# STM32F40x register map
File version: 1.5
Registers are 32-bit, read-write, reset 0x0 unless marked. A register's access mark holds for its fields unless they carry their own. Offsets are from the block's base; [hi:lo] are bit positions; {n}, {i} and the like mark numbered series; 'fields as' and 'values as' point back to an identical list.

## FSMC（静态存储器控制） — FSMC：NOR/PSRAM/NAND 外部存储器控制 | Flexible static memory controller
Base 0xA0000000
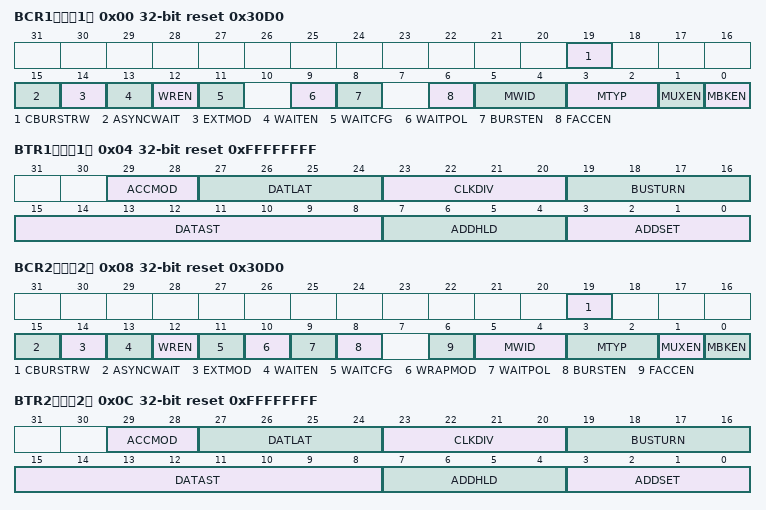
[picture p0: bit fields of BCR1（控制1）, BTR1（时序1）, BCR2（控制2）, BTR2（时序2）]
0x00 BCR1（控制1） reset 0x30D0 — 存储块1 控制（SRAM/PSRAM/NOR） | SRAM/NOR-Flash chip-select control register 1
  [19] CBURSTRW, [15] ASYNCWAIT, [14] EXTMOD, [13] WAITEN, [12] WREN, [11] WAITCFG, [9] WAITPOL, [8] BURSTEN, [6] FACCEN, [5:4] MWID, [3:2] MTYP, [1] MUXEN, [0] MBKEN
0x04 BTR1（时序1） reset 0xFFFFFFFF — 存储块1 读写时序 | SRAM/NOR-Flash chip-select timing register 1
  [29:28] ACCMOD, [27:24] DATLAT, [23:20] CLKDIV, [19:16] BUSTURN, [15:8] DATAST, [7:4] ADDHLD, [3:0] ADDSET
0x08 BCR2（控制2） reset 0x30D0 — 存储块2 控制 | SRAM/NOR-Flash chip-select control register 2
  [19] CBURSTRW, [15] ASYNCWAIT, [14] EXTMOD, [13] WAITEN, [12] WREN, [11] WAITCFG, [10] WRAPMOD, [9] WAITPOL, [8] BURSTEN, [6] FACCEN, [5:4] MWID, [3:2] MTYP, [1] MUXEN, [0] MBKEN
0x0C BTR2（时序2） reset 0xFFFFFFFF — 存储块2 读写时序 | SRAM/NOR-Flash chip-select timing register 2
  fields as BTR1（时序1）
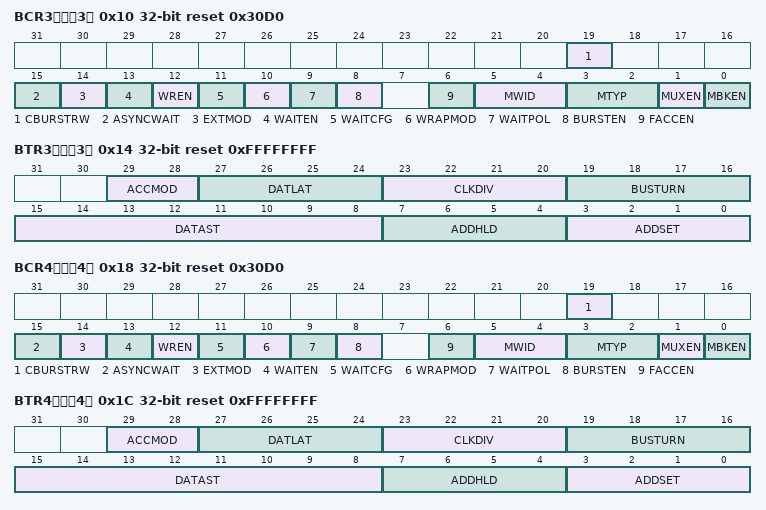
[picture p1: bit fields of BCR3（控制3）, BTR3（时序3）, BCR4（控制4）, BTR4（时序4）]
0x10 BCR3（控制3） reset 0x30D0 — 存储块3 控制 | SRAM/NOR-Flash chip-select control register 3
  fields as BCR2（控制2）
0x14 BTR3（时序3） reset 0xFFFFFFFF — 存储块3 读写时序 | SRAM/NOR-Flash chip-select timing register 3
  fields as BTR1（时序1）
0x18 BCR4（控制4） reset 0x30D0 — 存储块4 控制 | SRAM/NOR-Flash chip-select control register 4
  fields as BCR2（控制2）
0x1C BTR4（时序4） reset 0xFFFFFFFF — 存储块4 读写时序 | SRAM/NOR-Flash chip-select timing register 4
  fields as BTR1（时序1）
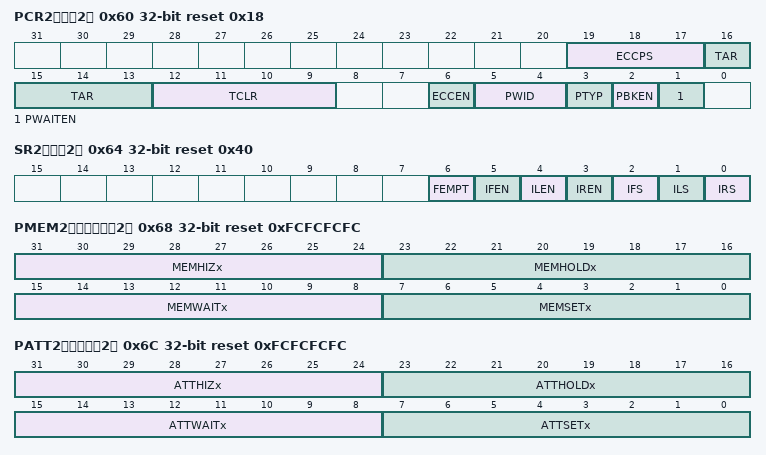
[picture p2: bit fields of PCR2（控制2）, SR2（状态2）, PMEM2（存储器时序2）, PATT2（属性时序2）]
0x60 PCR2（控制2） reset 0x18 — 存储块2 控制（NAND） | PC Card/NAND Flash control register 2
  [19:17] ECCPS, [16:13] TAR, [12:9] TCLR, [6] ECCEN, [5:4] PWID, [3] PTYP, [2] PBKEN, [1] PWAITEN
0x64 SR2（状态2） access per field reset 0x40 — 存储块2 状态（NAND） | FIFO status and interrupt register 2
  [6] FEMPT ro, [5] IFEN rw, [4] ILEN rw, [3] IREN rw, [2] IFS rw, [1] ILS rw, [0] IRS rw
0x68 PMEM2（存储器时序2） reset 0xFCFCFCFC — 存储块2 通用存储器时序（NAND） | Common memory space timing register 2
  [31:24] MEMHIZx, [23:16] MEMHOLDx, [15:8] MEMWAITx, [7:0] MEMSETx
0x6C PATT2（属性时序2） reset 0xFCFCFCFC — 存储块2 属性存储器时序（NAND） | Attribute memory space timing register 2
  [31:24] ATTHIZx, [23:16] ATTHOLDx, [15:8] ATTWAITx, [7:0] ATTSETx
0x74 ECCR2（块2 ECC） ro — 存储块2 ECC 结果（NAND） | ECC result register 2
  [31:0] ECCx
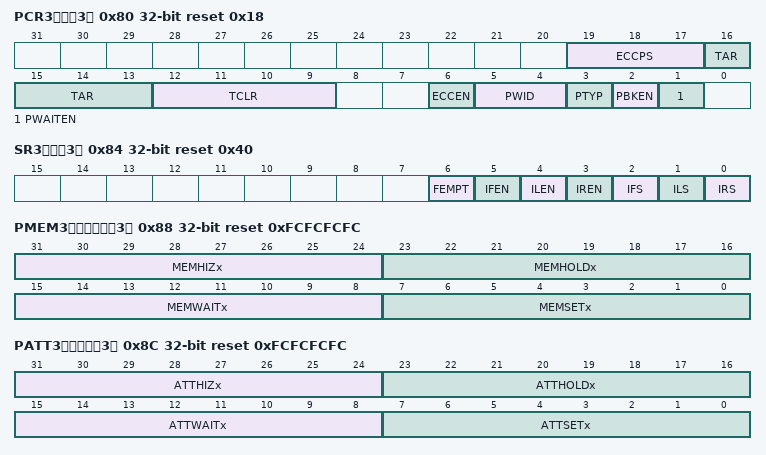
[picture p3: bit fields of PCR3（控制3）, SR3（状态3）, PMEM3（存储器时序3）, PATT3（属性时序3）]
0x80 PCR3（控制3） reset 0x18 — 存储块3 控制（NAND） | PC Card/NAND Flash control register 3
  fields as PCR2（控制2）
0x84 SR3（状态3） access per field reset 0x40 — 存储块3 状态（NAND） | FIFO status and interrupt register 3
  fields as SR2（状态2）
0x88 PMEM3（存储器时序3） reset 0xFCFCFCFC — 存储块3 通用存储器时序（NAND） | Common memory space timing register 3
  [31:24] MEMHIZx, [23:16] MEMHOLDx, [15:8] MEMWAITx, [7:0] MEMSETx
0x8C PATT3（属性时序3） reset 0xFCFCFCFC — 存储块3 属性存储器时序（NAND） | Attribute memory space timing register 3
  [31:24] ATTHIZx, [23:16] ATTHOLDx, [15:8] ATTWAITx, [7:0] ATTSETx
0x94 ECCR3（块3 ECC） ro — 存储块3 ECC 结果（NAND） | ECC result register 3
  [31:0] ECCx
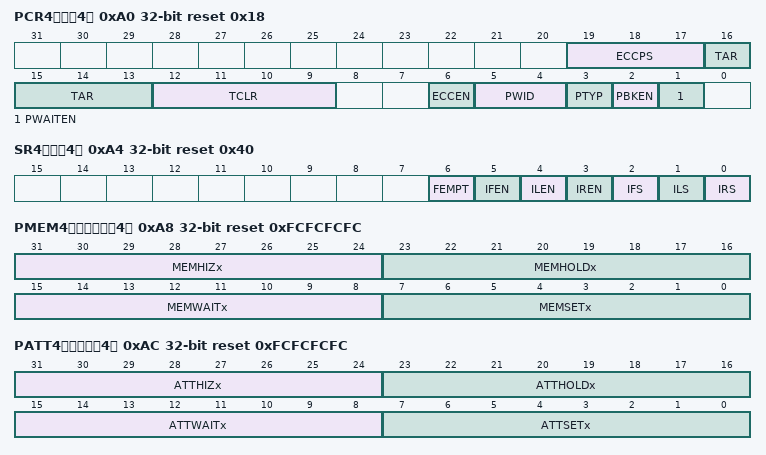
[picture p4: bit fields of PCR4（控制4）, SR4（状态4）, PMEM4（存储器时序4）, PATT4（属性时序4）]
0xA0 PCR4（控制4） reset 0x18 — 存储块4 控制（PCCard） | PC Card/NAND Flash control register 4
  fields as PCR2（控制2）
0xA4 SR4（状态4） access per field reset 0x40 — 存储块4 状态（PCCard） | FIFO status and interrupt register 4
  fields as SR2（状态2）
0xA8 PMEM4（存储器时序4） reset 0xFCFCFCFC — 存储块4 通用存储器时序（PCCard） | Common memory space timing register 4
  [31:24] MEMHIZx, [23:16] MEMHOLDx, [15:8] MEMWAITx, [7:0] MEMSETx
0xAC PATT4（属性时序4） reset 0xFCFCFCFC — 存储块4 属性存储器时序（PCCard） | Attribute memory space timing register 4
  [31:24] ATTHIZx, [23:16] ATTHOLDx, [15:8] ATTWAITx, [7:0] ATTSETx
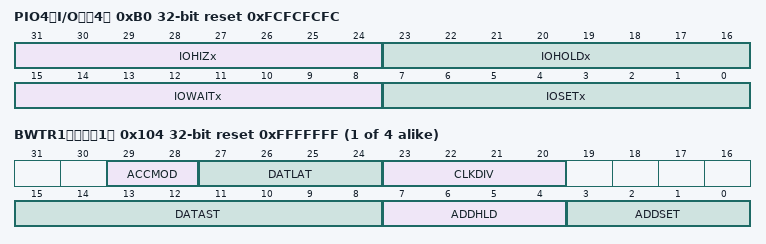
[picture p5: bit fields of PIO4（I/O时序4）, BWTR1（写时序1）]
0xB0 PIO4（I/O时序4） reset 0xFCFCFCFC — 存储块4 PCCard I/O 时序 | I/O space timing register 4
  [31:24] IOHIZx, [23:16] IOHOLDx, [15:8] IOWAITx, [7:0] IOSETx
{0xFC+8i} BWTR{i}（写时序{i}） reset 0xFFFFFFF (i=1..4) — 存储块{i} 写时序 | SRAM/NOR-Flash write timing registers {i}
  [29:28] ACCMOD, [27:24] DATLAT, [23:20] CLKDIV, [15:8] DATAST, [7:4] ADDHLD, [3:0] ADDSET
